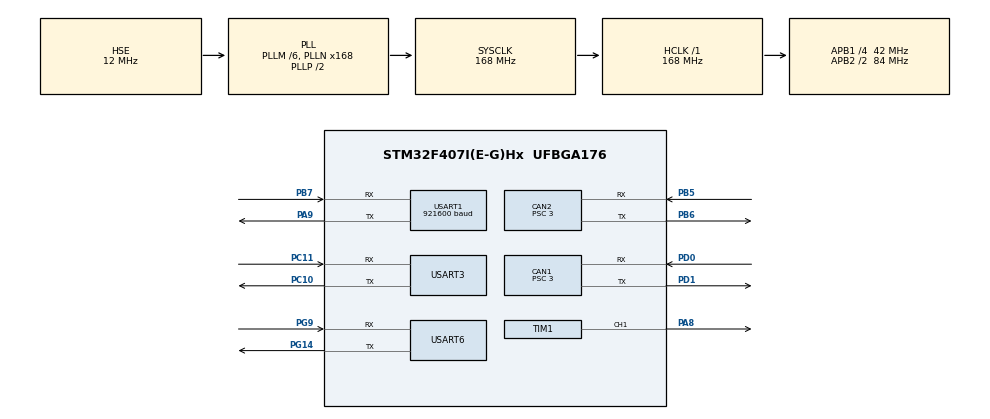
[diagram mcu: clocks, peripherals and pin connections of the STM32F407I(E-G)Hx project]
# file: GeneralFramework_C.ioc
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CAN1.BS1=CAN_BS1_10TQ
CAN1.BS2=CAN_BS2_3TQ
CAN1.CalculateBaudRate=1000000
CAN1.CalculateTimeBit=1000
CAN1.CalculateTimeQuantum=71.42857142857143
CAN1.Prescaler=3
CAN2.BS1=CAN_BS1_10TQ
CAN2.BS2=CAN_BS2_3TQ
CAN2.CalculateBaudRate=1000000
CAN2.CalculateTimeBit=1000
CAN2.CalculateTimeQuantum=71.42857142857143
CAN2.Prescaler=3
Dma.Request0=USART1_RX
Dma.Request1=USART1_TX
Dma.USART1_RX.0.Direction=DMA_PERIPH_TO_MEMORY
Dma.USART1_RX.0.FIFOMode=DMA_FIFOMODE_DISABLE
Dma.USART1_RX.0.Instance=DMA2_Stream2
Dma.USART1_RX.0.MemDataAlignment=DMA_MDATAALIGN_BYTE
Dma.USART1_RX.0.MemInc=DMA_MINC_ENABLE
Dma.USART1_RX.0.Mode=DMA_NORMAL
Dma.USART1_RX.0.PeriphDataAlignment=DMA_PDATAALIGN_BYTE
Dma.USART1_RX.0.PeriphInc=DMA_PINC_DISABLE
Dma.USART1_RX.0.Priority=DMA_PRIORITY_LOW
Dma.USART1_TX.1.Direction=DMA_MEMORY_TO_PERIPH
Dma.USART1_TX.1.FIFOMode=DMA_FIFOMODE_DISABLE
Dma.USART1_TX.1.Instance=DMA2_Stream7
Dma.USART1_TX.1.MemDataAlignment=DMA_MDATAALIGN_BYTE
Dma.USART1_TX.1.MemInc=DMA_MINC_ENABLE
Dma.USART1_TX.1.Mode=DMA_NORMAL
Dma.USART1_TX.1.PeriphDataAlignment=DMA_PDATAALIGN_BYTE
Dma.USART1_TX.1.PeriphInc=DMA_PINC_DISABLE
Dma.USART1_TX.1.Priority=DMA_PRIORITY_LOW
FREERTOS.INCLUDE_vTaskDelayUntil=1
FREERTOS.Tasks01=ApplicationTask,-1,512,Application,Default,NULL,Dynamic,NULL,NULL;RobotSystemTask,0,256,RobotSystem,Default,NULL,Dynamic,NULL,NULL;ControlTask,1,256,Control,Default,NULL,Dynamic,NULL,NULL;StateCoreTask,-3,512,StateCore,Default,NULL,Dynamic,NULL,NULL;Coroutine_0_Tas,-3,128,Coroutine_0,Default,NULL,Dynamic,NULL,NULL;Coroutine_1_Tas,-3,128,Coroutine_1,Default,NULL,Dynamic,NULL,NULL;Coroutine_2_Tas,-3,128,Coroutine_2,Default,NULL,Dynamic,NULL,NULL;Coroutine_3_Tas,-3,128,Coroutine_3,Default,NULL,Dynamic,NULL,NULL
Mcu.Family=STM32F4
Mcu.Name=STM32F407I(E-G)Hx
Mcu.Package=UFBGA176
NVIC.CAN1_RX0_IRQn=true\:5\:0\:false\:false\:true\:true\:true\:true\:true
NVIC.CAN1_RX1_IRQn=true\:5\:0\:false\:false\:true\:true\:true\:true\:true
NVIC.CAN1_TX_IRQn=true\:5\:0\:false\:false\:true\:true\:true\:true\:true
NVIC.CAN2_RX0_IRQn=true\:5\:0\:false\:false\:true\:true\:true\:true\:true
NVIC.CAN2_RX1_IRQn=true\:5\:0\:false\:false\:true\:true\:true\:true\:true
NVIC.CAN2_TX_IRQn=true\:5\:0\:false\:false\:true\:true\:true\:true\:true
NVIC.DMA2_Stream2_IRQn=true\:5\:0\:false\:false\:true\:true\:false\:true\:true
NVIC.DMA2_Stream7_IRQn=true\:5\:0\:false\:false\:true\:true\:false\:true\:true
NVIC.PriorityGroup=NVIC_PRIORITYGROUP_4
NVIC.TIM6_DAC_IRQn=true\:15\:0\:false\:false\:true\:false\:false\:true\:true
NVIC.TimeBase=TIM6_DAC_IRQn
NVIC.TimeBaseIP=TIM6
NVIC.USART1_IRQn=true\:5\:0\:false\:false\:true\:true\:true\:true\:true
NVIC.USART3_IRQn=true\:5\:0\:false\:false\:true\:true\:true\:true\:true
NVIC.USART6_IRQn=true\:5\:0\:false\:false\:true\:true\:true\:true\:true
PA13.Mode=Serial_Wire
PA13.Signal=SYS_JTMS-SWDIO
PA14.Mode=Serial_Wire
PA14.Signal=SYS_JTCK-SWCLK
PA8.Signal=S_TIM1_CH1
PA9.Mode=Asynchronous
PA9.Signal=USART1_TX
PB5.Mode=CAN_Activate
PB5.Signal=CAN2_RX
PB6.Mode=CAN_Activate
PB6.Signal=CAN2_TX
PB7.Mode=Asynchronous
PB7.Signal=USART1_RX
PC10.Mode=Asynchronous
PC10.Signal=USART3_TX
PC11.Mode=Asynchronous
PC11.Signal=USART3_RX
PD0.Mode=CAN_Activate
PD0.Signal=CAN1_RX
PD1.Mode=CAN_Activate
PD1.Signal=CAN1_TX
PG14.Mode=Asynchronous
PG14.Signal=USART6_TX
PG9.Mode=Asynchronous
PG9.Signal=USART6_RX
PH0-OSC_IN.Mode=HSE-External-Oscillator
PH0-OSC_IN.Signal=RCC_OSC_IN
PH1-OSC_OUT.Mode=HSE-External-Oscillator
PH1-OSC_OUT.Signal=RCC_OSC_OUT
ProjectManager.HeapSize=0x200
ProjectManager.StackSize=0x400
ProjectManager.TargetToolchain=MDK-ARM V5.32
RCC.48MHZClocksFreq_Value=84000000
RCC.AHBFreq_Value=168000000
RCC.APB1CLKDivider=RCC_HCLK_DIV4
RCC.APB1Freq_Value=42000000
RCC.APB1TimFreq_Value=84000000
RCC.APB2CLKDivider=RCC_HCLK_DIV2
RCC.APB2Freq_Value=84000000
RCC.APB2TimFreq_Value=168000000
RCC.CortexFreq_Value=168000000
RCC.HCLKFreq_Value=168000000
RCC.HSE_VALUE=12000000
RCC.HSI_VALUE=16000000
RCC.LSE_VALUE=32768
RCC.PLLM=6
RCC.PLLN=168
RCC.PLLSourceVirtual=RCC_PLLSOURCE_HSE
RCC.SYSCLKFreq_VALUE=168000000
RCC.SYSCLKSource=RCC_SYSCLKSOURCE_PLLCLK
RCC.VCOOutputFreq_Value=336000000
SH.S_TIM1_CH1.0=TIM1_CH1,PWM Generation1 CH1
STMicroelectronics.X-CUBE-ALGOBUILD.1.4.0.LibraryCcDSPOoLibraryJjDSPOoLibrary=true
TIM1.Channel-PWM\ Generation1\ CH1=TIM_CHANNEL_1
USART1.BaudRate=921600
USART1.VirtualMode=VM_ASYNC
USART3.VirtualMode=VM_ASYNC
USART6.VirtualMode=VM_ASYNC
VP_FREERTOS_VS_CMSIS_V1.Mode=CMSIS_V1
VP_STMicroelectronics.X-CUBE-ALGOBUILD_VS_DSPOoLibraryJjLibrary_1.4.0_1.4.0.Mode=DSPOoLibraryJjLibrary
VP_SYS_VS_tim6.Mode=TIM6
VP_TIM1_VS_ClockSourceINT.Mode=Internal
board=custom

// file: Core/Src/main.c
/* USER CODE BEGIN Header */
/**
  ******************************************************************************
  * @file           : main.c
  * @brief          : Main program body
  ******************************************************************************
  * @attention
  *
  * Copyright (c) 2026 STMicroelectronics.
  * All rights reserved.
  *
  * This software is licensed under terms that can be found in the LICENSE file
  * in the root directory of this software component.
  * If no LICENSE file comes with this software, it is provided AS-IS.
  *
  ******************************************************************************
  */
/* USER CODE END Header */
#include "main.h"
#include "cmsis_os.h"
#include "can.h"
#include "dma.h"
#include "tim.h"
#include "usart.h"
#include "gpio.h"

void SystemClock_Config(void);
void MX_FREERTOS_Init(void);

int main(void)
{

  /* MCU Configuration--------------------------------------------------------*/

  /* Reset of all peripherals, Initializes the Flash interface and the Systick. */
  HAL_Init();

  /* Configure the system clock */
  SystemClock_Config();

  /* Initialize all configured peripherals */
  MX_GPIO_Init();
  MX_DMA_Init();
  MX_CAN1_Init();
  MX_CAN2_Init();
  MX_USART3_UART_Init();
  MX_USART6_UART_Init();
  MX_TIM1_Init();
  MX_USART1_UART_Init();
  /* USER CODE BEGIN 2 */
  InitializeCpp();
  /* USER CODE END 2 */

  /* Call init function for freertos objects (in cmsis_os2.c) */
  MX_FREERTOS_Init();

  /* Start scheduler */
  osKernelStart();

  /* We should never get here as control is now taken by the scheduler */

  /* Infinite loop */
  while (1)
  {

  }
}

void SystemClock_Config(void)
{
  RCC_OscInitTypeDef RCC_OscInitStruct = {0};
  RCC_ClkInitTypeDef RCC_ClkInitStruct = {0};

  /** Configure the main internal regulator output voltage
  */
  __HAL_RCC_PWR_CLK_ENABLE();
  __HAL_PWR_VOLTAGESCALING_CONFIG(PWR_REGULATOR_VOLTAGE_SCALE1);

  /** Initializes the RCC Oscillators according to the specified parameters
  * in the RCC_OscInitTypeDef structure.
  */
  RCC_OscInitStruct.OscillatorType = RCC_OSCILLATORTYPE_HSE;
  RCC_OscInitStruct.HSEState = RCC_HSE_ON;
  RCC_OscInitStruct.PLL.PLLState = RCC_PLL_ON;
  RCC_OscInitStruct.PLL.PLLSource = RCC_PLLSOURCE_HSE;
  RCC_OscInitStruct.PLL.PLLM = 6;
  RCC_OscInitStruct.PLL.PLLN = 168;
  RCC_OscInitStruct.PLL.PLLP = RCC_PLLP_DIV2;
  RCC_OscInitStruct.PLL.PLLQ = 4;
  if (HAL_RCC_OscConfig(&RCC_OscInitStruct) != HAL_OK)
  {
    Error_Handler();
  }

  /** Initializes the CPU, AHB and APB buses clocks
  */
  RCC_ClkInitStruct.ClockType = RCC_CLOCKTYPE_HCLK|RCC_CLOCKTYPE_SYSCLK
                              |RCC_CLOCKTYPE_PCLK1|RCC_CLOCKTYPE_PCLK2;
  RCC_ClkInitStruct.SYSCLKSource = RCC_SYSCLKSOURCE_PLLCLK;
  RCC_ClkInitStruct.AHBCLKDivider = RCC_SYSCLK_DIV1;
  RCC_ClkInitStruct.APB1CLKDivider = RCC_HCLK_DIV4;
  RCC_ClkInitStruct.APB2CLKDivider = RCC_HCLK_DIV2;

  if (HAL_RCC_ClockConfig(&RCC_ClkInitStruct, FLASH_LATENCY_5) != HAL_OK)
  {
    Error_Handler();
  }
}

void HAL_TIM_PeriodElapsedCallback(TIM_HandleTypeDef *htim)
{
  if (htim->Instance == TIM6)
  {
    HAL_IncTick();
  }
}

void Error_Handler(void)
{
  __disable_irq();
  while (1)
  {
  }
}

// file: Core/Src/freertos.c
/* USER CODE BEGIN Header */
/**
  ******************************************************************************
  * File Name          : freertos.c
  * Description        : Code for freertos applications
  ******************************************************************************
  * @attention
  *
  * Copyright (c) 2026 STMicroelectronics.
  * All rights reserved.
  *
  * This software is licensed under terms that can be found in the LICENSE file
  * in the root directory of this software component.
  * If no LICENSE file comes with this software, it is provided AS-IS.
  *
  ******************************************************************************
  */
/* USER CODE END Header */

#include "FreeRTOS.h"
#include "task.h"
#include "main.h"
#include "cmsis_os.h"

/* USER CODE BEGIN Includes */
#include "std_cpp.h"
/* USER CODE END Includes */

osThreadId ApplicationTaskHandle;
osThreadId RobotSystemTaskHandle;
osThreadId ControlTaskHandle;
osThreadId StateCoreTaskHandle;
osThreadId Coroutine_0_TasHandle;
osThreadId Coroutine_1_TasHandle;
osThreadId Coroutine_2_TasHandle;
osThreadId Coroutine_3_TasHandle;

void Application(void const * argument);
void RobotSystem(void const * argument);
void Control(void const * argument);
void StateCore(void const * argument);
void Coroutine_0(void const * argument);
void Coroutine_1(void const * argument);
void Coroutine_2(void const * argument);
void Coroutine_3(void const * argument);

void MX_FREERTOS_Init(void); /* (MISRA C 2004 rule 8.1) */

/* GetIdleTaskMemory prototype (linked to static allocation support) */
void vApplicationGetIdleTaskMemory( StaticTask_t **ppxIdleTaskTCBBuffer, StackType_t **ppxIdleTaskStackBuffer, uint32_t *pulIdleTaskStackSize );

/* USER CODE BEGIN GET_IDLE_TASK_MEMORY */
static StaticTask_t xIdleTaskTCBBuffer;
static StackType_t xIdleStack[configMINIMAL_STACK_SIZE];

void vApplicationGetIdleTaskMemory( StaticTask_t **ppxIdleTaskTCBBuffer, StackType_t **ppxIdleTaskStackBuffer, uint32_t *pulIdleTaskStackSize )
{
  *ppxIdleTaskTCBBuffer = &xIdleTaskTCBBuffer;
  *ppxIdleTaskStackBuffer = &xIdleStack[0];
  *pulIdleTaskStackSize = configMINIMAL_STACK_SIZE;
  /* place for user code */
}
/* USER CODE END GET_IDLE_TASK_MEMORY */

void MX_FREERTOS_Init(void) {

  /* Create the thread(s) */
  /* definition and creation of ApplicationTask */
  osThreadDef(ApplicationTask, Application, osPriorityBelowNormal, 0, 512);
  ApplicationTaskHandle = osThreadCreate(osThread(ApplicationTask), NULL);

  /* definition and creation of RobotSystemTask */
  osThreadDef(RobotSystemTask, RobotSystem, osPriorityNormal, 0, 256);
  RobotSystemTaskHandle = osThreadCreate(osThread(RobotSystemTask), NULL);

  /* definition and creation of ControlTask */
  osThreadDef(ControlTask, Control, osPriorityAboveNormal, 0, 256);
  ControlTaskHandle = osThreadCreate(osThread(ControlTask), NULL);

  /* definition and creation of StateCoreTask */
  osThreadDef(StateCoreTask, StateCore, osPriorityIdle, 0, 512);
  StateCoreTaskHandle = osThreadCreate(osThread(StateCoreTask), NULL);

  /* definition and creation of Coroutine_0_Tas */
  osThreadDef(Coroutine_0_Tas, Coroutine_0, osPriorityIdle, 0, 128);
  Coroutine_0_TasHandle = osThreadCreate(osThread(Coroutine_0_Tas), NULL);

  /* definition and creation of Coroutine_1_Tas */
  osThreadDef(Coroutine_1_Tas, Coroutine_1, osPriorityIdle, 0, 128);
  Coroutine_1_TasHandle = osThreadCreate(osThread(Coroutine_1_Tas), NULL);

  /* definition and creation of Coroutine_2_Tas */
  osThreadDef(Coroutine_2_Tas, Coroutine_2, osPriorityIdle, 0, 128);
  Coroutine_2_TasHandle = osThreadCreate(osThread(Coroutine_2_Tas), NULL);

  /* definition and creation of Coroutine_3_Tas */
  osThreadDef(Coroutine_3_Tas, Coroutine_3, osPriorityIdle, 0, 128);
  Coroutine_3_TasHandle = osThreadCreate(osThread(Coroutine_3_Tas), NULL);

}

void Application(void const * argument)
{
  /* USER CODE BEGIN DEFAULT_TASK_FUNCTION */
  /* Infinite loop */
  ApplicationCpp();
  /* USER CODE END DEFAULT_TASK_FUNCTION */
}

void RobotSystem(void const * argument)
{
  /* USER CODE BEGIN RobotSystem */
  /* Infinite loop */
  RobotSystemCpp();
  /* USER CODE END RobotSystem */
}

void Control(void const * argument)
{
  /* USER CODE BEGIN Control */
  /* Infinite loop */
  ControlCpp();
  /* USER CODE END Control */
}

void StateCore(void const * argument)
{
  /* USER CODE BEGIN StateCore */
  /* Infinite loop */
  StateCoreCpp();
  /* USER CODE END StateCore */
}

void Coroutine_0(void const * argument)
{
  for(;;)
  {
    osDelay(1);
  }
}

void Coroutine_1(void const * argument)
{
  for(;;)
  {
    osDelay(1);
  }
}

void Coroutine_2(void const * argument)
{
  for(;;)
  {
    osDelay(1);
  }
}

void Coroutine_3(void const * argument)
{
  for(;;)
  {
    osDelay(1);
  }
}
